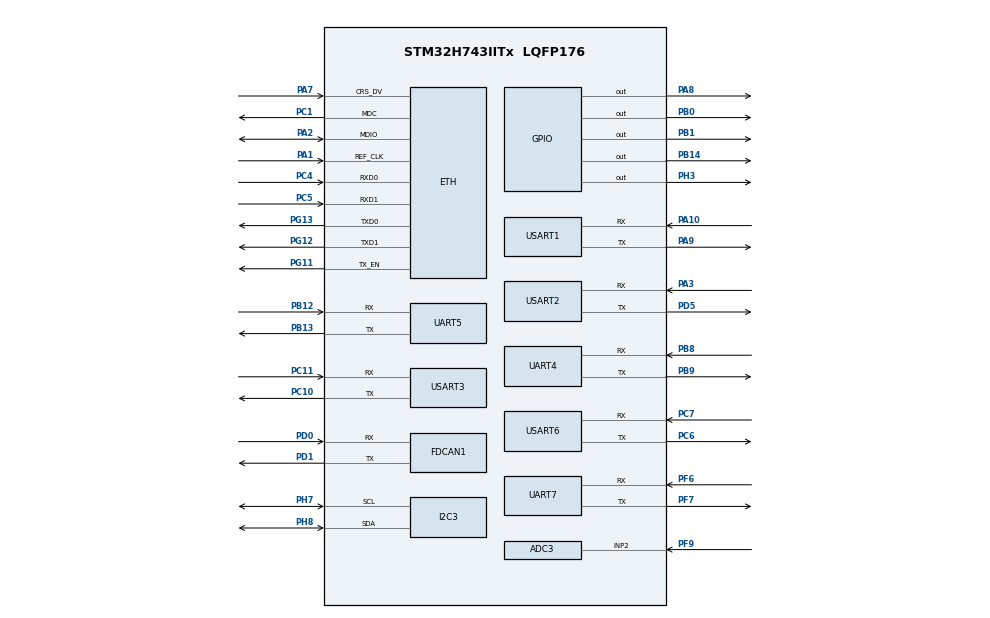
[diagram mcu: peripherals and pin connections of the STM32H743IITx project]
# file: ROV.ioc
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ADC3.Channel-0\#ChannelRegularConversion=ADC_CHANNEL_TEMPSENSOR
ADC3.ClockPrescaler=ADC_CLOCK_ASYNC_DIV4
ADC3.ClockPrescalerADC3=ADC_CLOCK_ASYNC_DIV4
ADC3.ConversionDataManagement=ADC_CONVERSIONDATA_DR
ADC3.ExternalTrigConv=ADC_SOFTWARE_START
ADC3.NbrOfConversionFlag=1
ADC3.OffsetNumber-0\#ChannelRegularConversion=ADC_OFFSET_NONE
ADC3.Overrun=ADC_OVR_DATA_OVERWRITTEN
ADC3.Rank-0\#ChannelRegularConversion=1
ADC3.SamplingTime-0\#ChannelRegularConversion=ADC_SAMPLETIME_2CYCLES_5
CORTEX_M7.AccessPermission-Cortex_Memory_Protection_Unit_Region0_Settings=MPU_REGION_FULL_ACCESS
CORTEX_M7.AccessPermission-Cortex_Memory_Protection_Unit_Region1_Settings=MPU_REGION_FULL_ACCESS
CORTEX_M7.BaseAddress-Cortex_Memory_Protection_Unit_Region0_Settings=0x30040000
CORTEX_M7.BaseAddress-Cortex_Memory_Protection_Unit_Region1_Settings=0x30044000
CORTEX_M7.CPU_DCache=Enabled
CORTEX_M7.CPU_ICache=Enabled
CORTEX_M7.Enable-Cortex_Memory_Protection_Unit_Region0_Settings=MPU_REGION_ENABLE
CORTEX_M7.Enable-Cortex_Memory_Protection_Unit_Region1_Settings=MPU_REGION_ENABLE
CORTEX_M7.IsBufferable-Cortex_Memory_Protection_Unit_Region0_Settings=MPU_ACCESS_BUFFERABLE
CORTEX_M7.IsCacheable-Cortex_Memory_Protection_Unit_Region0_Settings=MPU_ACCESS_NOT_CACHEABLE
CORTEX_M7.IsCacheable-Cortex_Memory_Protection_Unit_Region1_Settings=MPU_ACCESS_CACHEABLE
CORTEX_M7.IsShareable-Cortex_Memory_Protection_Unit_Region0_Settings=MPU_ACCESS_NOT_SHAREABLE
CORTEX_M7.MPU_Control=MPU_PRIVILEGED_DEFAULT
CORTEX_M7.Size-Cortex_Memory_Protection_Unit_Region0_Settings=MPU_REGION_SIZE_256B
CORTEX_M7.Size-Cortex_Memory_Protection_Unit_Region1_Settings=MPU_REGION_SIZE_16KB
Dma.Request0=USART1_TX
Dma.Request1=USART3_RX
Dma.Request10=UART4_TX
Dma.Request11=UART7_TX
Dma.Request2=USART3_TX
Dma.Request3=USART6_RX
Dma.Request4=USART6_TX
Dma.Request5=UART5_RX
Dma.Request6=UART5_TX
Dma.Request7=USART1_RX
Dma.Request8=USART2_TX
Dma.Request9=UART4_RX
Dma.UART4_RX.9.Direction=DMA_PERIPH_TO_MEMORY
Dma.UART4_RX.9.EventEnable=DISABLE
Dma.UART4_RX.9.FIFOMode=DMA_FIFOMODE_DISABLE
Dma.UART4_RX.9.Instance=DMA1_Stream7
Dma.UART4_RX.9.MemDataAlignment=DMA_MDATAALIGN_BYTE
Dma.UART4_RX.9.MemInc=DMA_MINC_ENABLE
Dma.UART4_RX.9.Mode=DMA_NORMAL
Dma.UART4_RX.9.PeriphDataAlignment=DMA_PDATAALIGN_BYTE
Dma.UART4_RX.9.PeriphInc=DMA_PINC_DISABLE
Dma.UART4_RX.9.Polarity=HAL_DMAMUX_REQ_GEN_RISING
Dma.UART4_RX.9.Priority=DMA_PRIORITY_LOW
Dma.UART4_RX.9.RequestNumber=1
Dma.UART4_RX.9.SignalID=NONE
Dma.UART4_RX.9.SyncEnable=DISABLE
Dma.UART4_RX.9.SyncPolarity=HAL_DMAMUX_SYNC_NO_EVENT
Dma.UART4_RX.9.SyncRequestNumber=1
Dma.UART4_RX.9.SyncSignalID=NONE
Dma.UART4_TX.10.Direction=DMA_MEMORY_TO_PERIPH
Dma.UART4_TX.10.EventEnable=DISABLE
Dma.UART4_TX.10.FIFOMode=DMA_FIFOMODE_DISABLE
Dma.UART4_TX.10.Instance=DMA2_Stream0
Dma.UART4_TX.10.MemDataAlignment=DMA_MDATAALIGN_BYTE
Dma.UART4_TX.10.MemInc=DMA_MINC_ENABLE
Dma.UART4_TX.10.Mode=DMA_NORMAL
Dma.UART4_TX.10.PeriphDataAlignment=DMA_PDATAALIGN_BYTE
Dma.UART4_TX.10.PeriphInc=DMA_PINC_DISABLE
Dma.UART4_TX.10.Polarity=HAL_DMAMUX_REQ_GEN_RISING
Dma.UART4_TX.10.Priority=DMA_PRIORITY_LOW
Dma.UART4_TX.10.RequestNumber=1
Dma.UART4_TX.10.SignalID=NONE
Dma.UART4_TX.10.SyncEnable=DISABLE
Dma.UART4_TX.10.SyncPolarity=HAL_DMAMUX_SYNC_NO_EVENT
Dma.UART4_TX.10.SyncRequestNumber=1
Dma.UART4_TX.10.SyncSignalID=NONE
Dma.UART5_RX.5.Direction=DMA_PERIPH_TO_MEMORY
Dma.UART5_RX.5.EventEnable=DISABLE
Dma.UART5_RX.5.FIFOMode=DMA_FIFOMODE_DISABLE
Dma.UART5_RX.5.Instance=DMA1_Stream3
Dma.UART5_RX.5.MemDataAlignment=DMA_MDATAALIGN_BYTE
Dma.UART5_RX.5.MemInc=DMA_MINC_ENABLE
Dma.UART5_RX.5.Mode=DMA_NORMAL
Dma.UART5_RX.5.PeriphDataAlignment=DMA_PDATAALIGN_BYTE
Dma.UART5_RX.5.PeriphInc=DMA_PINC_DISABLE
Dma.UART5_RX.5.Polarity=HAL_DMAMUX_REQ_GEN_RISING
Dma.UART5_RX.5.Priority=DMA_PRIORITY_LOW
Dma.UART5_RX.5.RequestNumber=1
Dma.UART5_RX.5.SignalID=NONE
Dma.UART5_RX.5.SyncEnable=DISABLE
Dma.UART5_RX.5.SyncPolarity=HAL_DMAMUX_SYNC_NO_EVENT
Dma.UART5_RX.5.SyncRequestNumber=1
Dma.UART5_RX.5.SyncSignalID=NONE
Dma.UART5_TX.6.Direction=DMA_MEMORY_TO_PERIPH
Dma.UART5_TX.6.EventEnable=DISABLE
Dma.UART5_TX.6.FIFOMode=DMA_FIFOMODE_DISABLE
Dma.UART5_TX.6.Instance=DMA1_Stream4
Dma.UART5_TX.6.MemDataAlignment=DMA_MDATAALIGN_BYTE
Dma.UART5_TX.6.MemInc=DMA_MINC_ENABLE
Dma.UART5_TX.6.Mode=DMA_NORMAL
Dma.UART5_TX.6.PeriphDataAlignment=DMA_PDATAALIGN_BYTE
Dma.UART5_TX.6.PeriphInc=DMA_PINC_DISABLE
Dma.UART5_TX.6.Polarity=HAL_DMAMUX_REQ_GEN_RISING
Dma.UART5_TX.6.Priority=DMA_PRIORITY_LOW
Dma.UART5_TX.6.RequestNumber=1
Dma.UART5_TX.6.SignalID=NONE
Dma.UART5_TX.6.SyncEnable=DISABLE
Dma.UART5_TX.6.SyncPolarity=HAL_DMAMUX_SYNC_NO_EVENT
Dma.UART5_TX.6.SyncRequestNumber=1
Dma.UART5_TX.6.SyncSignalID=NONE
Dma.UART7_TX.11.Direction=DMA_MEMORY_TO_PERIPH
Dma.UART7_TX.11.EventEnable=DISABLE
Dma.UART7_TX.11.FIFOMode=DMA_FIFOMODE_DISABLE
Dma.UART7_TX.11.Instance=DMA2_Stream3
Dma.UART7_TX.11.MemDataAlignment=DMA_MDATAALIGN_BYTE
Dma.UART7_TX.11.MemInc=DMA_MINC_ENABLE
Dma.UART7_TX.11.Mode=DMA_NORMAL
Dma.UART7_TX.11.PeriphDataAlignment=DMA_PDATAALIGN_BYTE
Dma.UART7_TX.11.PeriphInc=DMA_PINC_DISABLE
Dma.UART7_TX.11.Polarity=HAL_DMAMUX_REQ_GEN_RISING
Dma.UART7_TX.11.Priority=DMA_PRIORITY_LOW
Dma.UART7_TX.11.RequestNumber=1
Dma.UART7_TX.11.SignalID=NONE
Dma.UART7_TX.11.SyncEnable=DISABLE
Dma.UART7_TX.11.SyncPolarity=HAL_DMAMUX_SYNC_NO_EVENT
Dma.UART7_TX.11.SyncRequestNumber=1
Dma.UART7_TX.11.SyncSignalID=NONE
Dma.USART1_RX.7.Direction=DMA_PERIPH_TO_MEMORY
Dma.USART1_RX.7.EventEnable=DISABLE
Dma.USART1_RX.7.FIFOMode=DMA_FIFOMODE_DISABLE
Dma.USART1_RX.7.Instance=DMA1_Stream2
Dma.USART1_RX.7.MemDataAlignment=DMA_MDATAALIGN_BYTE
Dma.USART1_RX.7.MemInc=DMA_MINC_ENABLE
Dma.USART1_RX.7.Mode=DMA_NORMAL
Dma.USART1_RX.7.PeriphDataAlignment=DMA_PDATAALIGN_BYTE
Dma.USART1_RX.7.PeriphInc=DMA_PINC_DISABLE
Dma.USART1_RX.7.Polarity=HAL_DMAMUX_REQ_GEN_RISING
Dma.USART1_RX.7.Priority=DMA_PRIORITY_LOW
Dma.USART1_RX.7.RequestNumber=1
Dma.USART1_RX.7.SignalID=NONE
Dma.USART1_RX.7.SyncEnable=DISABLE
Dma.USART1_RX.7.SyncPolarity=HAL_DMAMUX_SYNC_NO_EVENT
Dma.USART1_RX.7.SyncRequestNumber=1
Dma.USART1_RX.7.SyncSignalID=NONE
Dma.USART1_TX.0.Direction=DMA_MEMORY_TO_PERIPH
Dma.USART1_TX.0.EventEnable=DISABLE
Dma.USART1_TX.0.FIFOMode=DMA_FIFOMODE_DISABLE
Dma.USART1_TX.0.Instance=DMA2_Stream7
Dma.USART1_TX.0.MemDataAlignment=DMA_MDATAALIGN_BYTE
Dma.USART1_TX.0.MemInc=DMA_MINC_ENABLE
Dma.USART1_TX.0.Mode=DMA_NORMAL
Dma.USART1_TX.0.PeriphDataAlignment=DMA_PDATAALIGN_BYTE
Dma.USART1_TX.0.PeriphInc=DMA_PINC_DISABLE
Dma.USART1_TX.0.Polarity=HAL_DMAMUX_REQ_GEN_RISING
Dma.USART1_TX.0.Priority=DMA_PRIORITY_LOW
Dma.USART1_TX.0.RequestNumber=1
Dma.USART1_TX.0.SignalID=NONE
Dma.USART1_TX.0.SyncEnable=DISABLE
Dma.USART1_TX.0.SyncPolarity=HAL_DMAMUX_SYNC_NO_EVENT
Dma.USART1_TX.0.SyncRequestNumber=1
Dma.USART1_TX.0.SyncSignalID=NONE
Dma.USART2_TX.8.Direction=DMA_MEMORY_TO_PERIPH
Dma.USART2_TX.8.EventEnable=DISABLE
Dma.USART2_TX.8.FIFOMode=DMA_FIFOMODE_DISABLE
Dma.USART2_TX.8.Instance=DMA1_Stream6
Dma.USART2_TX.8.MemDataAlignment=DMA_MDATAALIGN_BYTE
Dma.USART2_TX.8.MemInc=DMA_MINC_ENABLE
Dma.USART2_TX.8.Mode=DMA_NORMAL
Dma.USART2_TX.8.PeriphDataAlignment=DMA_PDATAALIGN_BYTE
Dma.USART2_TX.8.PeriphInc=DMA_PINC_DISABLE
Dma.USART2_TX.8.Polarity=HAL_DMAMUX_REQ_GEN_RISING
Dma.USART2_TX.8.Priority=DMA_PRIORITY_LOW
Dma.USART2_TX.8.RequestNumber=1
Dma.USART2_TX.8.SignalID=NONE
Dma.USART2_TX.8.SyncEnable=DISABLE
Dma.USART2_TX.8.SyncPolarity=HAL_DMAMUX_SYNC_NO_EVENT
Dma.USART2_TX.8.SyncRequestNumber=1
Dma.USART2_TX.8.SyncSignalID=NONE
Dma.USART3_RX.1.Direction=DMA_PERIPH_TO_MEMORY
Dma.USART3_RX.1.EventEnable=DISABLE
Dma.USART3_RX.1.FIFOMode=DMA_FIFOMODE_DISABLE
Dma.USART3_RX.1.Instance=DMA1_Stream1
Dma.USART3_RX.1.MemDataAlignment=DMA_MDATAALIGN_BYTE
Dma.USART3_RX.1.MemInc=DMA_MINC_ENABLE
Dma.USART3_RX.1.Mode=DMA_NORMAL
Dma.USART3_RX.1.PeriphDataAlignment=DMA_PDATAALIGN_BYTE
Dma.USART3_RX.1.PeriphInc=DMA_PINC_DISABLE
Dma.USART3_RX.1.Polarity=HAL_DMAMUX_REQ_GEN_RISING
Dma.USART3_RX.1.Priority=DMA_PRIORITY_HIGH
Dma.USART3_RX.1.RequestNumber=1
Dma.USART3_RX.1.SignalID=NONE
Dma.USART3_RX.1.SyncEnable=DISABLE
Dma.USART3_RX.1.SyncPolarity=HAL_DMAMUX_SYNC_NO_EVENT
Dma.USART3_RX.1.SyncRequestNumber=1
Dma.USART3_RX.1.SyncSignalID=NONE
Dma.USART3_TX.2.Direction=DMA_MEMORY_TO_PERIPH
Dma.USART3_TX.2.EventEnable=DISABLE
Dma.USART3_TX.2.FIFOMode=DMA_FIFOMODE_DISABLE
Dma.USART3_TX.2.Instance=DMA1_Stream0
Dma.USART3_TX.2.MemDataAlignment=DMA_MDATAALIGN_BYTE
Dma.USART3_TX.2.MemInc=DMA_MINC_ENABLE
Dma.USART3_TX.2.Mode=DMA_NORMAL
Dma.USART3_TX.2.PeriphDataAlignment=DMA_PDATAALIGN_BYTE
Dma.USART3_TX.2.PeriphInc=DMA_PINC_DISABLE
Dma.USART3_TX.2.Polarity=HAL_DMAMUX_REQ_GEN_RISING
Dma.USART3_TX.2.Priority=DMA_PRIORITY_MEDIUM
Dma.USART3_TX.2.RequestNumber=1
Dma.USART3_TX.2.SignalID=NONE
Dma.USART3_TX.2.SyncEnable=DISABLE
Dma.USART3_TX.2.SyncPolarity=HAL_DMAMUX_SYNC_NO_EVENT
Dma.USART3_TX.2.SyncRequestNumber=1
Dma.USART3_TX.2.SyncSignalID=NONE
Dma.USART6_RX.3.Direction=DMA_PERIPH_TO_MEMORY
Dma.USART6_RX.3.EventEnable=DISABLE
Dma.USART6_RX.3.FIFOMode=DMA_FIFOMODE_DISABLE
Dma.USART6_RX.3.Instance=DMA2_Stream1
Dma.USART6_RX.3.MemDataAlignment=DMA_MDATAALIGN_BYTE
Dma.USART6_RX.3.MemInc=DMA_MINC_ENABLE
Dma.USART6_RX.3.Mode=DMA_NORMAL
Dma.USART6_RX.3.PeriphDataAlignment=DMA_PDATAALIGN_BYTE
Dma.USART6_RX.3.PeriphInc=DMA_PINC_DISABLE
Dma.USART6_RX.3.Polarity=HAL_DMAMUX_REQ_GEN_RISING
Dma.USART6_RX.3.Priority=DMA_PRIORITY_HIGH
Dma.USART6_RX.3.RequestNumber=1
Dma.USART6_RX.3.SignalID=NONE
Dma.USART6_RX.3.SyncEnable=DISABLE
Dma.USART6_RX.3.SyncPolarity=HAL_DMAMUX_SYNC_NO_EVENT
Dma.USART6_RX.3.SyncRequestNumber=1
Dma.USART6_RX.3.SyncSignalID=NONE
Dma.USART6_TX.4.Direction=DMA_MEMORY_TO_PERIPH
Dma.USART6_TX.4.EventEnable=DISABLE
Dma.USART6_TX.4.FIFOMode=DMA_FIFOMODE_DISABLE
Dma.USART6_TX.4.Instance=DMA2_Stream6
Dma.USART6_TX.4.MemDataAlignment=DMA_MDATAALIGN_BYTE
Dma.USART6_TX.4.MemInc=DMA_MINC_ENABLE
Dma.USART6_TX.4.Mode=DMA_NORMAL
Dma.USART6_TX.4.PeriphDataAlignment=DMA_PDATAALIGN_BYTE
Dma.USART6_TX.4.PeriphInc=DMA_PINC_DISABLE
Dma.USART6_TX.4.Polarity=HAL_DMAMUX_REQ_GEN_RISING
Dma.USART6_TX.4.Priority=DMA_PRIORITY_MEDIUM
Dma.USART6_TX.4.RequestNumber=1
Dma.USART6_TX.4.SignalID=NONE
Dma.USART6_TX.4.SyncEnable=DISABLE
Dma.USART6_TX.4.SyncPolarity=HAL_DMAMUX_SYNC_NO_EVENT
Dma.USART6_TX.4.SyncRequestNumber=1
Dma.USART6_TX.4.SyncSignalID=NONE
ETH.MediaInterface=HAL_ETH_RMII_MODE
ETH.RxBuffLen=1524
FDCAN1.CalculateBaudRateNominal=249999
FDCAN1.CalculateTimeBitNominal=4000
FDCAN1.CalculateTimeQuantumNominal=166.66666666666669
FDCAN1.NominalPrescaler=20
FDCAN1.NominalTimeSeg1=15
FDCAN1.NominalTimeSeg2=8
FDCAN1.RxFifo0ElmtsNbr=32
FDCAN1.TxFifoQueueElmtsNbr=32
FREERTOS.Tasks01=defaultTask,0,128,StartDefaultTask,Default,NULL
FREERTOS.configTOTAL_HEAP_SIZE=30720
FREERTOS.configUSE_NEWLIB_REENTRANT=1
I2C3.Timing=0x307075B1
LWIP.BSP.number=1
LWIP.GATEWAY_ADDRESS=192.168.001.001
LWIP.IP_ADDRESS=192.168.001.025
LWIP.LWIP_DHCP=0
LWIP.NETMASK_ADDRESS=255.255.255.000
LWIP.Version=v2.1.2_Cube
LWIP0.BSP.STBoard=false
LWIP0.BSP.api=BSP_COMPONENT_DRIVER
LWIP0.BSP.component=LAN8742
LWIP0.BSP.instance=LAN8742
LWIP0.BSP.name=Driver_PHY
LWIP0.BSP.solution=LAN8742
Mcu.Family=STM32H7
Mcu.Name=STM32H743IITx
Mcu.Package=LQFP176
NVIC.DMA1_Stream0_IRQn=true\:5\:0\:true\:false\:true\:true\:false\:true\:true
NVIC.DMA1_Stream1_IRQn=true\:5\:0\:true\:false\:true\:true\:false\:true\:true
NVIC.DMA1_Stream2_IRQn=true\:5\:0\:false\:false\:true\:true\:false\:true\:true
NVIC.DMA1_Stream3_IRQn=true\:5\:0\:false\:false\:true\:true\:false\:true\:true
NVIC.DMA1_Stream4_IRQn=true\:5\:0\:false\:false\:true\:true\:false\:true\:true
NVIC.DMA1_Stream6_IRQn=true\:5\:0\:false\:false\:true\:true\:false\:true\:true
NVIC.DMA1_Stream7_IRQn=true\:5\:0\:false\:false\:true\:true\:false\:true\:true
NVIC.DMA2_Stream0_IRQn=true\:5\:0\:false\:false\:true\:true\:false\:true\:true
NVIC.DMA2_Stream1_IRQn=true\:5\:0\:false\:false\:true\:true\:false\:true\:true
NVIC.DMA2_Stream3_IRQn=true\:5\:0\:false\:false\:true\:true\:false\:true\:true
NVIC.DMA2_Stream6_IRQn=true\:5\:0\:false\:false\:true\:true\:false\:true\:true
NVIC.DMA2_Stream7_IRQn=true\:5\:0\:false\:false\:true\:true\:false\:true\:true
NVIC.ETH_IRQn=true\:5\:0\:false\:false\:true\:true\:true\:true\:true
NVIC.FDCAN1_IT0_IRQn=true\:6\:0\:true\:false\:true\:true\:true\:true\:true
NVIC.PriorityGroup=NVIC_PRIORITYGROUP_4
NVIC.TIM1_UP_IRQn=true\:0\:0\:false\:false\:true\:false\:false\:true\:true
NVIC.TIM2_IRQn=true\:5\:0\:false\:false\:false\:true\:true\:true\:true
NVIC.TimeBase=TIM1_UP_IRQn
NVIC.TimeBaseIP=TIM1
NVIC.UART4_IRQn=true\:5\:0\:false\:false\:false\:true\:true\:true\:true
NVIC.UART5_IRQn=true\:5\:0\:false\:false\:false\:true\:true\:true\:true
NVIC.UART7_IRQn=true\:5\:0\:false\:false\:false\:true\:true\:true\:true
NVIC.USART1_IRQn=true\:5\:0\:false\:false\:false\:true\:true\:true\:true
NVIC.USART2_IRQn=true\:5\:0\:false\:false\:false\:true\:true\:true\:true
NVIC.USART3_IRQn=true\:4\:0\:true\:false\:false\:false\:true\:true\:true
NVIC.USART6_IRQn=true\:4\:0\:true\:false\:false\:false\:true\:true\:true
PA1.GPIO_Mode=GPIO_MODE_AF_PP
PA1.GPIO_PuPd=GPIO_NOPULL
PA1.GPIO_Speed=GPIO_SPEED_FREQ_VERY_HIGH
PA1.Mode=RMII
PA1.Signal=ETH_REF_CLK
PA10.Mode=Asynchronous
PA10.Signal=USART1_RX
PA13\ (JTMS/SWDIO).Mode=Serial_Wire
PA13\ (JTMS/SWDIO).Signal=DEBUG_JTMS-SWDIO
PA14\ (JTCK/SWCLK).Mode=Serial_Wire
PA14\ (JTCK/SWCLK).Signal=DEBUG_JTCK-SWCLK
PA2.GPIO_Mode=GPIO_MODE_AF_PP
PA2.GPIO_PuPd=GPIO_NOPULL
PA2.GPIO_Speed=GPIO_SPEED_FREQ_VERY_HIGH
PA2.Mode=RMII
PA2.Signal=ETH_MDIO
PA3.Mode=Asynchronous
PA3.Signal=USART2_RX
PA7.GPIO_Mode=GPIO_MODE_AF_PP
PA7.GPIO_PuPd=GPIO_NOPULL
PA7.GPIO_Speed=GPIO_SPEED_FREQ_VERY_HIGH
PA7.Mode=RMII
PA7.Signal=ETH_CRS_DV
PA8.Signal=GPIO_Output
PA9.Mode=Asynchronous
PA9.Signal=USART1_TX
PB0.GPIO_PuPd=GPIO_PULLUP
PB0.Signal=GPIO_Output
PB1.GPIO_PuPd=GPIO_PULLUP
PB1.Signal=GPIO_Output
PB12.Mode=Asynchronous
PB12.Signal=UART5_RX
PB13.Mode=Asynchronous
PB13.Signal=UART5_TX
PB14.Signal=GPIO_Output
PB8.Mode=Asynchronous
PB8.Signal=UART4_RX
PB9.Mode=Asynchronous
PB9.Signal=UART4_TX
PC1.Mode=RMII
PC1.Signal=ETH_MDC
PC10.Mode=Asynchronous
PC10.Signal=USART3_TX
PC11.Mode=Asynchronous
PC11.Signal=USART3_RX
PC4.GPIO_Mode=GPIO_MODE_AF_PP
PC4.GPIO_PuPd=GPIO_NOPULL
PC4.GPIO_Speed=GPIO_SPEED_FREQ_VERY_HIGH
PC4.Mode=RMII
PC4.Signal=ETH_RXD0
PC5.GPIO_Mode=GPIO_MODE_AF_PP
PC5.GPIO_PuPd=GPIO_NOPULL
PC5.GPIO_Speed=GPIO_SPEED_FREQ_VERY_HIGH
PC5.Mode=RMII
PC5.Signal=ETH_RXD1
PC6.Mode=Asynchronous
PC6.Signal=USART6_TX
PC7.Mode=Asynchronous
PC7.Signal=USART6_RX
PD0.GPIO_PuPd=GPIO_PULLUP
PD0.GPIO_Speed=GPIO_SPEED_FREQ_VERY_HIGH
PD0.Mode=FDCAN_Activate
PD0.Signal=FDCAN1_RX
PD1.GPIO_PuPd=GPIO_PULLUP
PD1.GPIO_Speed=GPIO_SPEED_FREQ_VERY_HIGH
PD1.Mode=FDCAN_Activate
PD1.Signal=FDCAN1_TX
PD5.Mode=Asynchronous
PD5.Signal=USART2_TX
PF6.Mode=Asynchronous
PF6.Signal=UART7_RX
PF7.Mode=Asynchronous
PF7.Signal=UART7_TX
PF9.Mode=IN2-Single-Ended
PF9.Signal=ADC3_INP2
PG11.GPIO_Mode=GPIO_MODE_AF_PP
PG11.GPIO_PuPd=GPIO_NOPULL
PG11.GPIO_Speed=GPIO_SPEED_FREQ_VERY_HIGH
PG11.Mode=RMII
PG11.Signal=ETH_TX_EN
PG12.GPIO_Mode=GPIO_MODE_AF_PP
PG12.GPIO_PuPd=GPIO_NOPULL
PG12.GPIO_Speed=GPIO_SPEED_FREQ_VERY_HIGH
PG12.Mode=RMII
PG12.Signal=ETH_TXD1
PG13.GPIO_Mode=GPIO_MODE_AF_PP
PG13.GPIO_PuPd=GPIO_NOPULL
PG13.GPIO_Speed=GPIO_SPEED_FREQ_VERY_HIGH
PG13.Mode=RMII
PG13.Signal=ETH_TXD0
PH0-OSC_IN\ (PH0).Mode=HSE-External-Oscillator
PH0-OSC_IN\ (PH0).Signal=RCC_OSC_IN
PH1-OSC_OUT\ (PH1).Mode=HSE-External-Oscillator
PH1-OSC_OUT\ (PH1).Signal=RCC_OSC_OUT
PH3.Signal=GPIO_Output
PH4.GPIO_Pu=GPIO_PULLUP
PH4.Signal=I2C2_SCL
PH5.GPIO_Pu=GPIO_PULLUP
PH5.Signal=I2C2_SDA
PH7.Mode=I2C
PH7.Signal=I2C3_SCL
PH8.Mode=I2C
PH8.Signal=I2C3_SDA
ProjectManager.HeapSize=0x200
ProjectManager.StackSize=0x2000
ProjectManager.TargetToolchain=STM32CubeIDE
RCC.ADCFreq_Value=72000000
RCC.APB1Freq_Value=120000000
RCC.APB2Freq_Value=120000000
RCC.APB3Freq_Value=120000000
RCC.APB4Freq_Value=120000000
RCC.CortexFreq_Value=480000000
RCC.D1PPRE=RCC_APB3_DIV2
RCC.D2PPRE1=RCC_APB1_DIV2
RCC.D2PPRE2=RCC_APB2_DIV2
RCC.D3PPRE=RCC_APB4_DIV2
RCC.DIVM1=5
RCC.DIVM2=25
RCC.DIVM3=5
RCC.DIVN1=192
RCC.DIVN2=504
RCC.DIVN3=192
RCC.DIVP2=7
RCC.DIVQ1=8
RCC.DIVQ2=7
RCC.DIVR3=32
RCC.HCLKFreq_Value=240000000
RCC.HPRE=RCC_HCLK_DIV2
RCC.PLL2FRACN=0
RCC.PLLFRACN=0
RCC.PLLSourceVirtual=RCC_PLLSOURCE_HSE
RCC.ProductRev=revV
RCC.SYSCLKFreq_VALUE=480000000
RCC.SYSCLKSource=RCC_SYSCLKSOURCE_PLLCLK
RCC.USBFreq_Value=120000000
TIM2.Period=5000-1
TIM2.Prescaler=240-1
USART1.FIFOMode=FIFOMODE_ENABLE
USART1.VirtualMode-Asynchronous=VM_ASYNC
USART2.VirtualMode-Asynchronous=VM_ASYNC
USART3.VirtualMode-Asynchronous=VM_ASYNC
USART6.VirtualMode-Asynchronous=VM_ASYNC
VP_ADC3_TempSens_Input.Mode=IN-TempSens
VP_ADC3_Vref_Input.Mode=IN-Vrefint
VP_CRC_VS_CRC.Mode=CRC_Activate
VP_FREERTOS_VS_CMSIS_V1.Mode=CMSIS_V1
VP_LWIP_VS_Enabled.Mode=Enabled
VP_SYS_VS_tim1.Mode=TIM1
VP_TIM2_VS_ClockSourceINT.Mode=Internal
board=custom

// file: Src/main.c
/* USER CODE BEGIN Header */
/**
  ******************************************************************************
  * @file           : main.c
  * @brief          : Main program body
  ******************************************************************************
  * @attention
  *
  * Copyright (c) 2023 STMicroelectronics.
  * All rights reserved.
  *
  * This software is licensed under terms that can be found in the LICENSE file
  * in the root directory of this software component.
  * If no LICENSE file comes with this software, it is provided AS-IS.
  *
  ******************************************************************************
  */
/* USER CODE END Header */
#include "main.h"
#include "cmsis_os.h"
#include "adc.h"
#include "crc.h"
#include "dma.h"
#include "fdcan.h"
#include "i2c.h"
#include "lwip.h"
#include "tim.h"
#include "usart.h"
#include "gpio.h"

void SystemClock_Config(void);
static void MPU_Config(void);
void MX_FREERTOS_Init(void);

int main(void)
{

  /* MPU Configuration--------------------------------------------------------*/
  MPU_Config();

  /* Enable I-Cache---------------------------------------------------------*/
  SCB_EnableICache();

  /* Enable D-Cache---------------------------------------------------------*/
  SCB_EnableDCache();

  /* MCU Configuration--------------------------------------------------------*/

  /* Reset of all peripherals, Initializes the Flash interface and the Systick. */
  HAL_Init();

  /* Configure the system clock */
  SystemClock_Config();

  /* Initialize all configured peripherals */
  MX_GPIO_Init();
  MX_DMA_Init();
  MX_FDCAN1_Init();
  MX_ADC3_Init();
  MX_CRC_Init();
  MX_USART1_UART_Init();
  MX_USART3_UART_Init();
  MX_USART6_UART_Init();
  MX_TIM2_Init();
  MX_UART5_Init();
  MX_I2C3_Init();
  MX_UART4_Init();
  MX_UART7_Init();
  MX_USART2_UART_Init();

  /* Call init function for freertos objects (in freertos.c) */
  MX_FREERTOS_Init();

  /* Start scheduler */
  osKernelStart();
  /* We should never get here as control is now taken by the scheduler */
  /* Infinite loop */
  while (1)
  {

  }
}

void SystemClock_Config(void)
{
  RCC_OscInitTypeDef RCC_OscInitStruct = {0};
  RCC_ClkInitTypeDef RCC_ClkInitStruct = {0};

  /** Supply configuration update enable
  */
  HAL_PWREx_ConfigSupply(PWR_LDO_SUPPLY);

  /** Configure the main internal regulator output voltage
  */
  __HAL_PWR_VOLTAGESCALING_CONFIG(PWR_REGULATOR_VOLTAGE_SCALE1);

  while(!__HAL_PWR_GET_FLAG(PWR_FLAG_VOSRDY)) {}

  __HAL_RCC_SYSCFG_CLK_ENABLE();
  __HAL_PWR_VOLTAGESCALING_CONFIG(PWR_REGULATOR_VOLTAGE_SCALE0);

  while(!__HAL_PWR_GET_FLAG(PWR_FLAG_VOSRDY)) {}

  /** Initializes the RCC Oscillators according to the specified parameters
  * in the RCC_OscInitTypeDef structure.
  */
  RCC_OscInitStruct.OscillatorType = RCC_OSCILLATORTYPE_HSE;
  RCC_OscInitStruct.HSEState = RCC_HSE_ON;
  RCC_OscInitStruct.PLL.PLLState = RCC_PLL_ON;
  RCC_OscInitStruct.PLL.PLLSource = RCC_PLLSOURCE_HSE;
  RCC_OscInitStruct.PLL.PLLM = 5;
  RCC_OscInitStruct.PLL.PLLN = 192;
  RCC_OscInitStruct.PLL.PLLP = 2;
  RCC_OscInitStruct.PLL.PLLQ = 8;
  RCC_OscInitStruct.PLL.PLLR = 2;
  RCC_OscInitStruct.PLL.PLLRGE = RCC_PLL1VCIRANGE_2;
  RCC_OscInitStruct.PLL.PLLVCOSEL = RCC_PLL1VCOWIDE;
  RCC_OscInitStruct.PLL.PLLFRACN = 0;
  if (HAL_RCC_OscConfig(&RCC_OscInitStruct) != HAL_OK)
  {
    Error_Handler();
  }

  /** Initializes the CPU, AHB and APB buses clocks
  */
  RCC_ClkInitStruct.ClockType = RCC_CLOCKTYPE_HCLK|RCC_CLOCKTYPE_SYSCLK
                              |RCC_CLOCKTYPE_PCLK1|RCC_CLOCKTYPE_PCLK2
                              |RCC_CLOCKTYPE_D3PCLK1|RCC_CLOCKTYPE_D1PCLK1;
  RCC_ClkInitStruct.SYSCLKSource = RCC_SYSCLKSOURCE_PLLCLK;
  RCC_ClkInitStruct.SYSCLKDivider = RCC_SYSCLK_DIV1;
  RCC_ClkInitStruct.AHBCLKDivider = RCC_HCLK_DIV2;
  RCC_ClkInitStruct.APB3CLKDivider = RCC_APB3_DIV2;
  RCC_ClkInitStruct.APB1CLKDivider = RCC_APB1_DIV2;
  RCC_ClkInitStruct.APB2CLKDivider = RCC_APB2_DIV2;
  RCC_ClkInitStruct.APB4CLKDivider = RCC_APB4_DIV2;

  if (HAL_RCC_ClockConfig(&RCC_ClkInitStruct, FLASH_LATENCY_4) != HAL_OK)
  {
    Error_Handler();
  }
}

/* MPU Configuration */

void MPU_Config(void)
{
  MPU_Region_InitTypeDef MPU_InitStruct = {0};

  /* Disables the MPU */
  HAL_MPU_Disable();

  /** Initializes and configures the Region and the memory to be protected
  */
  MPU_InitStruct.Enable = MPU_REGION_ENABLE;
  MPU_InitStruct.Number = MPU_REGION_NUMBER0;
  MPU_InitStruct.BaseAddress = 0x30040000;
  MPU_InitStruct.Size = MPU_REGION_SIZE_256B;
  MPU_InitStruct.SubRegionDisable = 0x0;
  MPU_InitStruct.TypeExtField = MPU_TEX_LEVEL0;
  MPU_InitStruct.AccessPermission = MPU_REGION_FULL_ACCESS;
  MPU_InitStruct.DisableExec = MPU_INSTRUCTION_ACCESS_ENABLE;
  MPU_InitStruct.IsShareable = MPU_ACCESS_NOT_SHAREABLE;
  MPU_InitStruct.IsCacheable = MPU_ACCESS_NOT_CACHEABLE;
  MPU_InitStruct.IsBufferable = MPU_ACCESS_BUFFERABLE;

  HAL_MPU_ConfigRegion(&MPU_InitStruct);

  /** Initializes and configures the Region and the memory to be protected
  */
  MPU_InitStruct.Number = MPU_REGION_NUMBER1;
  MPU_InitStruct.BaseAddress = 0x30044000;
  MPU_InitStruct.Size = MPU_REGION_SIZE_16KB;
  MPU_InitStruct.IsCacheable = MPU_ACCESS_CACHEABLE;
  MPU_InitStruct.IsBufferable = MPU_ACCESS_NOT_BUFFERABLE;

  HAL_MPU_ConfigRegion(&MPU_InitStruct);
  /* Enables the MPU */
  HAL_MPU_Enable(MPU_PRIVILEGED_DEFAULT);

}

void HAL_TIM_PeriodElapsedCallback(TIM_HandleTypeDef *htim)
{
  if (htim->Instance == TIM1) {
    HAL_IncTick();
  }
}

void Error_Handler(void)
{
  __disable_irq();
  while (1)
  {
  }
}

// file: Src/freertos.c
/* USER CODE BEGIN Header */
/**
  ******************************************************************************
  * File Name          : freertos.c
  * Description        : Code for freertos applications
  ******************************************************************************
  * @attention
  *
  * Copyright (c) 2023 STMicroelectronics.
  * All rights reserved.
  *
  * This software is licensed under terms that can be found in the LICENSE file
  * in the root directory of this software component.
  * If no LICENSE file comes with this software, it is provided AS-IS.
  *
  ******************************************************************************
  */
/* USER CODE END Header */

#include "FreeRTOS.h"
#include "task.h"
#include "main.h"
#include "cmsis_os.h"

osThreadId defaultTaskHandle;

void StartDefaultTask(void const * argument);

extern void MX_LWIP_Init(void);
void MX_FREERTOS_Init(void); /* (MISRA C 2004 rule 8.1) */

/* GetIdleTaskMemory prototype (linked to static allocation support) */
void vApplicationGetIdleTaskMemory( StaticTask_t **ppxIdleTaskTCBBuffer, StackType_t **ppxIdleTaskStackBuffer, uint32_t *pulIdleTaskStackSize );

/* USER CODE BEGIN GET_IDLE_TASK_MEMORY */
static StaticTask_t xIdleTaskTCBBuffer;
static StackType_t xIdleStack[configMINIMAL_STACK_SIZE];

void vApplicationGetIdleTaskMemory( StaticTask_t **ppxIdleTaskTCBBuffer, StackType_t **ppxIdleTaskStackBuffer, uint32_t *pulIdleTaskStackSize )
{
  *ppxIdleTaskTCBBuffer = &xIdleTaskTCBBuffer;
  *ppxIdleTaskStackBuffer = &xIdleStack[0];
  *pulIdleTaskStackSize = configMINIMAL_STACK_SIZE;
  /* place for user code */
}
/* USER CODE END GET_IDLE_TASK_MEMORY */

void MX_FREERTOS_Init(void) {

  /* Create the thread(s) */
  /* definition and creation of defaultTask */
  osThreadDef(defaultTask, StartDefaultTask, osPriorityNormal, 0, 128);
  defaultTaskHandle = osThreadCreate(osThread(defaultTask), NULL);

}

void StartDefaultTask(void const * argument)
{
  /* init code for LWIP */
  MX_LWIP_Init();
  /* USER CODE BEGIN StartDefaultTask */
  /* Infinite loop */
  for(;;)
  {
    osDelay(1000);
  }
  /* USER CODE END StartDefaultTask */
}
